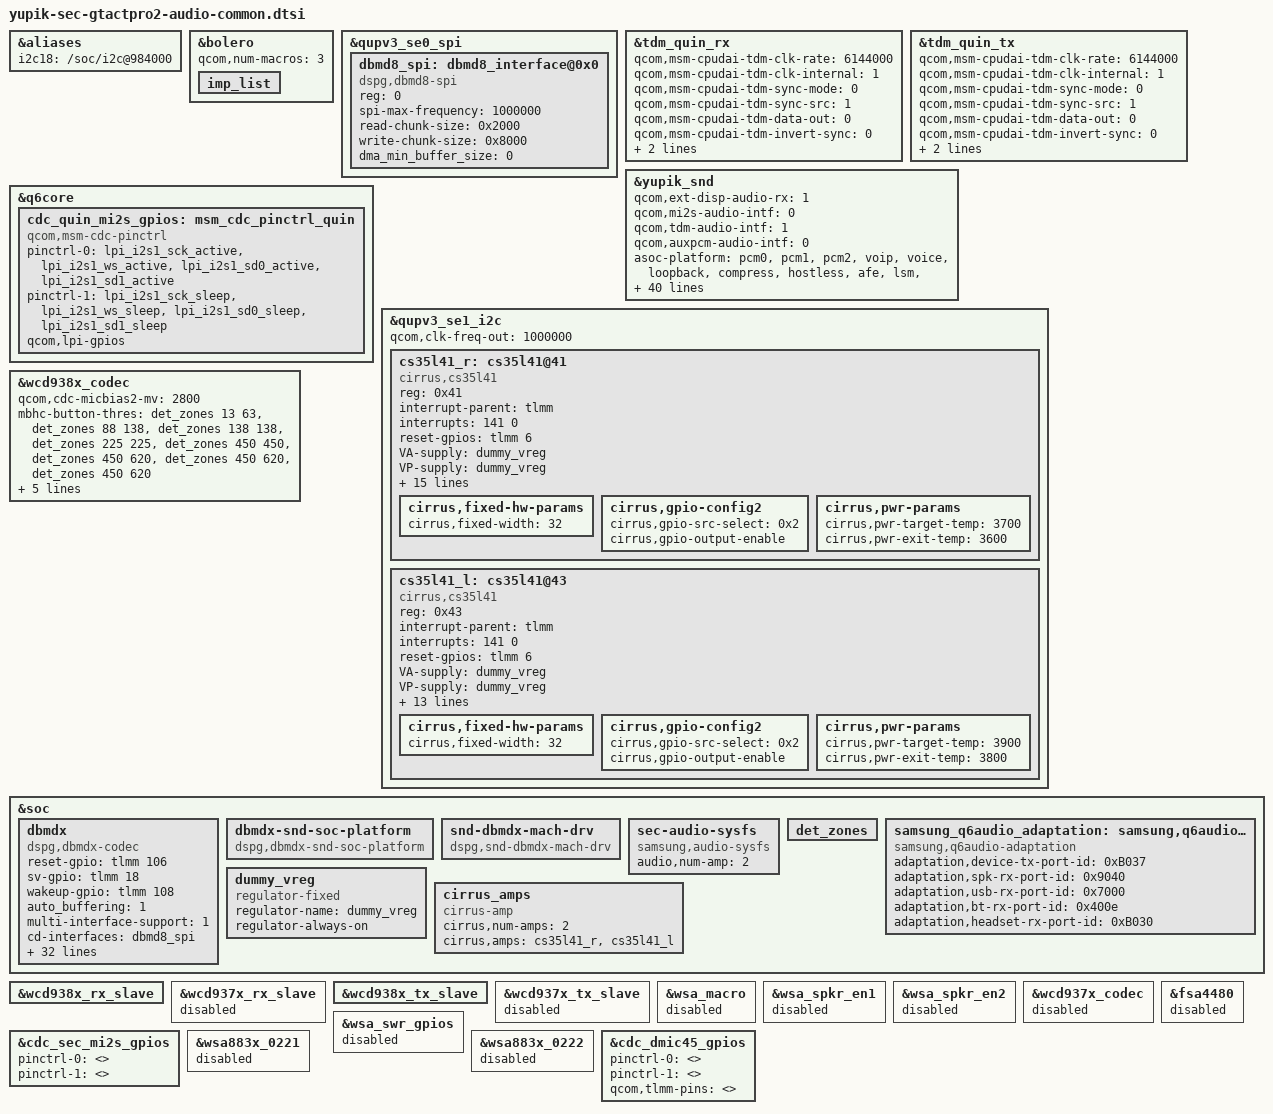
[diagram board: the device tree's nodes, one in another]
/* Copyright (c) 2019, The Linux Foundation. All rights reserved.
 *
 * This program is free software; you can redistribute it and/or modify
 * it under the terms of the GNU General Public License version 2 and
 * only version 2 as published by the Free Software Foundation.
 *
 * This program is distributed in the hope that it will be useful,
 * but WITHOUT ANY WARRANTY; without even the implied warranty of
 * MERCHANTABILITY or FITNESS FOR A PARTICULAR PURPOSE.  See the
 * GNU General Public License for more details.
 */

&aliases {
	i2c18 = "/soc/i2c@984000";
};

&bolero {
	qcom,num-macros = <3>;
	imp_list: imp_list {
		#list-imp-cells = <3>;
	};
};

&qupv3_se0_spi {
	status = "okay";
	dbmd8_spi:dbmd8_interface@0x0  {
		compatible = "dspg,dbmd8-spi";
		reg = <0>;
		spi-max-frequency = <1000000>;
		read-chunk-size  = <0x2000> ;
		write-chunk-size = <0x8000> ;
		dma_min_buffer_size = <0>;
	};
};

&tdm_quin_rx {
	qcom,msm-cpudai-tdm-clk-rate = <6144000>;
	qcom,msm-cpudai-tdm-clk-internal = <1>;
	qcom,msm-cpudai-tdm-sync-mode = <0>;
	qcom,msm-cpudai-tdm-sync-src = <1>;
	qcom,msm-cpudai-tdm-data-out = <0>;
	qcom,msm-cpudai-tdm-invert-sync = <0>;
	qcom,msm-cpudai-tdm-data-delay = <1>;
	qcom,msm-cpudai-tdm-clk-attribute = /bits/ 16 <1>;
};

&tdm_quin_tx {
	qcom,msm-cpudai-tdm-clk-rate = <6144000>;
	qcom,msm-cpudai-tdm-clk-internal = <1>;
	qcom,msm-cpudai-tdm-sync-mode = <0>;
	qcom,msm-cpudai-tdm-sync-src = <1>;
	qcom,msm-cpudai-tdm-data-out = <0>;
	qcom,msm-cpudai-tdm-invert-sync = <0>;
	qcom,msm-cpudai-tdm-data-delay = <1>;
	qcom,msm-cpudai-tdm-clk-attribute = /bits/ 16 <1>;
};

&yupik_snd {
	qcom,ext-disp-audio-rx = <1>;
	qcom,mi2s-audio-intf = <0>;
	qcom,tdm-audio-intf = <1>;
	qcom,auxpcm-audio-intf = <0>;

	asoc-platform = <&pcm0>, <&pcm1>, <&pcm2>, <&voip>, <&voice>,
			<&loopback>, <&compress>, <&hostless>,
			<&afe>, <&lsm>, <&routing>, <&compr>,
			<&pcm_noirq>, <&samsung_q6audio_adaptation>;
	asoc-platform-names = "msm-pcm-dsp.0", "msm-pcm-dsp.1",
			"msm-pcm-dsp.2", "msm-voip-dsp",
			"msm-pcm-voice", "msm-pcm-loopback",
			"msm-compress-dsp", "msm-pcm-hostless",
			"msm-pcm-afe", "msm-lsm-client",
			"msm-pcm-routing", "msm-compr-dsp",
			"msm-pcm-dsp-noirq", "q6audio-adaptation";
	asoc-codec  = <&stub_codec>, <&bolero>,
		      <&wcd938x_codec>,
		      <&ext_disp_audio_codec>;
	asoc-codec-names = "msm-stub-codec.1", "bolero_codec",
			   "wcd938x_codec",
			   "msm-ext-disp-audio-codec-rx";
	qcom,audio-routing =
		"AMIC1", "Analog Mic1",
		"Analog Mic1", "MIC BIAS1",
		"AMIC2", "Analog Mic2",
		"Analog Mic2", "MIC BIAS2",
		"AMIC3", "Analog Mic3",
		"Analog Mic3", "MIC BIAS1",
		"AMIC4", "Analog Mic4",
		"Analog Mic4", "MIC BIAS3",
		"IN1_HPHL", "HPHL_OUT",
		"IN2_HPHR", "HPHR_OUT",
		"RX_TX DEC0_INP", "TX DEC0 MUX",
		"RX_TX DEC1_INP", "TX DEC1 MUX",
		"RX_TX DEC2_INP", "TX DEC2 MUX",
		"RX_TX DEC3_INP", "TX DEC3 MUX",
		"TX SWR_INPUT", "WCD_TX_OUTPUT",
		"VA SWR_INPUT", "VA_SWR_CLK",
		"VA SWR_INPUT", "WCD_TX_OUTPUT",
		"VA_AIF1 CAP", "VA_SWR_CLK",
		"VA_AIF2 CAP", "VA_SWR_CLK",
		"VA_AIF3 CAP", "VA_SWR_CLK",
		"AMP0 SPK", "Left AMP SPK",
		"AMP1 SPK", "Right AMP SPK";

	qcom,msm-mbhc-hs-mic-max-threshold-mv = <9999>;
	qcom,msm-mbhc-hs-mic-min-threshold-mv = <640>;
	qcom,cdc-dmic01-gpios = <>;
	qcom,cdc-dmic23-gpios = <>;
	qcom,cdc-dmic45-gpios = <>;
	qcom,sec-mi2s-gpios = <>;
	qcom,quin-mi2s-gpios = <&cdc_quin_mi2s_gpios>;
	qcom,wsa-max-devs = <0>;
	fsa4480-i2c-handle = <>;
	qcom,msm-mbhc-gnd-det = <1>;
	qcom,tdm-max-slots = <4>;
	qcom,codec-conf = <0x12>; /* CS35L41 stereo*/
};

&q6core {
	cdc_quin_mi2s_gpios: msm_cdc_pinctrl_quin {
		compatible = "qcom,msm-cdc-pinctrl";
		pinctrl-names = "aud_active", "aud_sleep";
		pinctrl-0 = <&lpi_i2s1_sck_active &lpi_i2s1_ws_active
				 &lpi_i2s1_sd0_active &lpi_i2s1_sd1_active>;
		pinctrl-1 = <&lpi_i2s1_sck_sleep &lpi_i2s1_ws_sleep
				 &lpi_i2s1_sd0_sleep &lpi_i2s1_sd1_sleep>;
		qcom,lpi-gpios;
		#gpio-cells = <0>;
	};
};

&qupv3_se1_i2c {
	qcom,clk-freq-out = <1000000>;
	status = "ok";

	/* For Cirrus AMP (CS35L41)*/
	cs35l41_r: cs35l41@41 {
		#sound-dai-cells = <1>;
		compatible = "cirrus,cs35l41";
		reg = <0x41>;
		interrupt-parent = <&tlmm>;
		interrupts = <141 0>;
		reset-gpios = <&tlmm 6 0>;
		VA-supply = <&dummy_vreg>;
		VP-supply = <&dummy_vreg>;
		cirrus,asp-sdout-hiz = <0x3>;

		cirrus,dsp-part-name = "cs35l40-bot";
		cirrus,right-channel-amp;
		cirrus,mfd-suffix = "_r";
		cirrus,bd-suffix = "_1";
		cirrus,use-fsync-errata;
		cirrus,bd-max-temp = <110>;

		cirrus,dsp-noise-gate-enable;
		cirrus,dsp-noise-gate-delay = <0x4>;
		cirrus,dsp-noise-gate-threshold = <0x6>;

		cirrus,hw-noise-gate-select = <0x3F>;
		cirrus,hw-noise-gate-delay = <0x4>;
		cirrus,hw-noise-gate-threshold = <0x6>;
		cirrus,boost-peak-milliamp = <4100>;

		pinctrl-names = "default";
		pinctrl-0 = <&cs35l41_gpio_default>;

		cirrus,fixed-hw-params	{
			cirrus,fixed-width = <32>;
		};

		cirrus,gpio-config2 {
			cirrus,gpio-src-select = <0x2>;
			cirrus,gpio-output-enable;
		};

		cirrus,pwr-params {
			cirrus,pwr-target-temp = <3700>;
			cirrus,pwr-exit-temp = <3600>;
		};
	};

	cs35l41_l: cs35l41@43 {
		#sound-dai-cells = <1>;
		compatible = "cirrus,cs35l41";
		reg = <0x43>;
		interrupt-parent = <&tlmm>;
		interrupts = <141 0>;
		reset-gpios = <&tlmm 6 0>;
		VA-supply = <&dummy_vreg>;
		VP-supply = <&dummy_vreg>;
		cirrus,asp-sdout-hiz = <0x3>;

		cirrus,dsp-part-name = "cs35l40-rcv";
		cirrus,mfd-suffix = "";
		cirrus,bd-suffix = "_0";
		cirrus,use-fsync-errata;
		cirrus,bd-max-temp = <100>;

		cirrus,dsp-noise-gate-enable;
		cirrus,dsp-noise-gate-delay = <0x4>;
		cirrus,dsp-noise-gate-threshold = <0x6>;

		cirrus,hw-noise-gate-select = <0x3F>;
		cirrus,hw-noise-gate-delay = <0x4>;
		cirrus,hw-noise-gate-threshold = <0x6>;
		cirrus,boost-peak-milliamp = <4100>;

		cirrus,fixed-hw-params	{
			cirrus,fixed-width = <32>;
		};

		cirrus,gpio-config2 {
			cirrus,gpio-src-select = <0x2>;
			cirrus,gpio-output-enable;
		};

		cirrus,pwr-params {
			cirrus,pwr-target-temp = <3900>;
			cirrus,pwr-exit-temp = <3800>;
		};
	};
};

&wcd938x_codec {
	status = "ok";
	qcom,cdc-micbias2-mv = <2800>;
	mbhc-button-thres = <&det_zones 13 63>,
		 <&det_zones 88 138>,
		 <&det_zones 138 138>,
		 <&det_zones 225 225>,
		 <&det_zones 450 450>,
		 <&det_zones 450 620>,
		 <&det_zones 450 620>,
		 <&det_zones 450 620>;
	imp-table = <&imp_list 0 5 6>,
			 <&imp_list 6 23 8>,
			 <&imp_list 24 38 7>,
			 <&imp_list 39 100 6>,
			 <&imp_list 101 160 10>,
			 <&imp_list 161 400 11>,
			 <&imp_list 401 2000 11>,
			 <&imp_list 2001 0x7fffffff 6>;
};

&soc {
	dbmdx {
		status = "okay";
		compatible = "dspg,dbmdx-codec";
		reset-gpio = <&tlmm 106 0>;
		sv-gpio = <&tlmm 18 0>;
		wakeup-gpio = <&tlmm 108 0>;
		auto_buffering = <1>;
		multi-interface-support = <1>;
		cd-interfaces = <&dbmd8_spi>;
		va-interfaces = <0 0 0 0>;
		feature-va; /* enable VA */
		va-firmware-name = "dbmd8_va_fw.bin";
		va-asrp-params-firmware-name = "dbmd8_va_asrp_fw.bin";
		va-config =	<0x80000000
				0x80000000
				0x80000000
				0x80290020
				0x801b0020
				0x80093004
				0x802210E1
				0x8033006E
				0x80159494
				0x80230000
				0x801A0001
				0x80107009
				0x8aab0040
				0x800C7530
				0x80000000
				0x80000000
				0x80000000
				0x80000000>;
				/* 2MIC_NR_DET 1MIC_DET 2MIC_NR_STREAM 2MIC_NONR_STREAM IDLE */
		va-ns-config = <0x80000000 0x80000000 0x80000000 0x80000000 0x80000000
				0x80000000 0x80000000 0x80000000 0x80000000 0x80000000
				0x80000000 0x80000000 0x80000000 0x80000000 0x80000000
				0x803D0109 0x80000000 0x803D0109 0x80000000 0x80000000
				0x803E0000 0x80000000 0x803E0000 0x80000000 0x8aab0014
				0x80340243 0x80340040 0x80340243 0x80340040 0x8013FFFF
				0x8aab0014 0x8aab0014 0x8aab0014 0x8aab0014 0x8aab0014
				0x80110E10 0x8013FFF0 0x80110E10 0x8013FFF0 0x80340000
				0x80111EEE 0x80000000 0x80111EEE 0x80000000 0x8aab0014
				0x80112EEE 0x80000000 0x80112EE2 0x80000000 0x80000000
				0x80113EEE 0x80000000 0x80113EEE 0x80000000 0x80000000
				0x80114EEE 0x80000000 0x80114EEE 0x80000000 0x80000000
				0x80115EE2 0x80000000 0x80115EE2 0x80000000 0x80000000
				0x80116EEE 0x80000000 0x80116EEE 0x80000000 0x80000000
				0x80117EEE 0x80000000 0x80117EEE 0x80000000 0x80000000
				0x8013FF20 0x80000000 0x8013FFF2 0x80000000 0x80000000
				0x80000000 0x80000000 0x80000000 0x80000000 0x80000000
				0x80000000 0x80000000 0x80000000 0x80000000 0x80000000
				0x80000000 0x80000000 0x80000000 0x80000000 0x80000000
				0x80000000 0x80000000 0x80000000 0x80000000 0x80000000
				0x80000000 0x80000000 0x80000000 0x80000000 0x80000000
				0x80000000 0x80000000 0x80000000 0x80000000 0x80000000
				0x80000000 0x80000000 0x80000000 0x80000000 0x80000000>;


		va-speeds = <0x0000 460800  0 1000000
			     0x0000 2000000 0 3000000
			     0x0000 3000000 0 5000000>;
		va-mic-config = <0x868 0x0167 0x8>;
		va-mic-mode = <2>;

		master-clk-rate = <32768>;
		/* constant-clk-rate = <32768>; */
		firmware_id = <0xdbd8>;
		use_gpio_for_wakeup = <1>; /* Use wakeup gpio */
		wakeup_set_value = <0>;  /* Value to write to wakeup gpio */
		auto_detection = <1>;
		detection_buffer_channels = <1>;
		min_samples_chunk_size = <128>;
		pcm_streaming_mode = <1>;
		boot_options = <0x220>; /* Verify chip id */
		send_uevent_on_detection = <1>;
		send_uevent_after_buffering = <0>;
		detection_after_buffering = <0>;
		va_backlog_length = <1802>;
		va_backlog_length_okg = <1000>;
		amodel_options = <0x1b>;
		va_ns_supported = <1>;
		va_ns-num_of_configs = <5>;
		mic_config_source = <0>;
		retrigger_interval_sec = <600>;
	};

	dbmdx-snd-soc-platform {
		compatible = "dspg,dbmdx-snd-soc-platform";
	};

	snd-dbmdx-mach-drv {
		compatible = "dspg,snd-dbmdx-mach-drv";
	};

	sec-audio-sysfs {
		compatible = "samsung,audio-sysfs";
		status = "okay";
		audio,num-amp = <2>;
	};

	det_zones: det_zones {
		#list-det-cells = <2>;
	};

	samsung_q6audio_adaptation: samsung,q6audio-adaptation {
		compatible = "samsung,q6audio-adaptation";
		adaptation,device-tx-port-id = <0xB037>;
		adaptation,spk-rx-port-id = <0x9040>;
		adaptation,usb-rx-port-id = <0x7000>;
		adaptation,bt-rx-port-id = <0x400e>;
		adaptation,headset-rx-port-id = <0xB030>;
	};

	dummy_vreg: dummy_vreg {
		compatible = "regulator-fixed";
		status = "ok";
		regulator-name = "dummy_vreg";
		regulator-always-on;
	};

	cirrus_amps {
		compatible = "cirrus-amp";
		cirrus,num-amps = <2>;
		cirrus,amps = <&cs35l41_r &cs35l41_l>;
	};
};

&wcd938x_rx_slave {
	status = "okay";
};

&wcd937x_rx_slave {
	status = "disabled";
};

&wcd938x_tx_slave {
	status = "okay";
};

&wcd937x_tx_slave {
	status = "disabled";
};

&wsa_macro {
	status = "disabled";
};

&wsa_spkr_en1 {
	status = "disabled";
};

&wsa_spkr_en2 {
	status = "disabled";
};

&wcd937x_codec {
	status = "disabled";
};

&cdc_sec_mi2s_gpios {
	pinctrl-0 = <>;
	pinctrl-1 = <>;
};

&fsa4480 {
	status = "disabled";
};

&wsa_swr_gpios {
	status = "disabled";
};

&wsa883x_0221 {
	status = "disabled";
};

&wsa883x_0222 {
	status = "disabled";
};

&cdc_dmic45_gpios {
	pinctrl-0 = <>;
	pinctrl-1 = <>;
	qcom,tlmm-pins = <>;
};

